# STM32N655 register map
File version: 1.0
CPU: CM55 r0p1, little endian, no MPU, FPU, vendor SysTick, 8 interrupt priority bits
Registers are 32-bit, read-write, reset 0x0 unless marked. A register's access mark holds for its fields unless they carry their own. Offsets are from the block's base; [hi:lo] are bit positions; 'fields as' and 'values as' point back to an identical list.

## XSPI1 — Extended-SPI interface
Base 0x48025000
Same registers: XSPI2 0x4802A000, XSPI3 0x4802D000, XSPI1_S 0x58025000, XSPI2_S 0x5802A000, XSPI3_S 0x5802D000
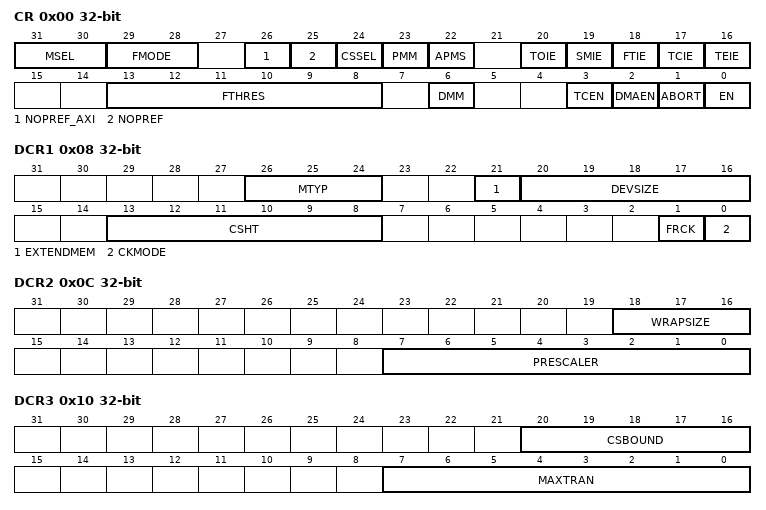
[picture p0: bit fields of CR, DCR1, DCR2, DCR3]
0x00 CR — XSPI control register
  [31:30] MSEL — Flash select
  [29:28] FMODE — Functional mode
  [26] NOPREF_AXI — no prefetch for signaled AXI transactions
  [25] NOPREF — no prefetch data
  [24] CSSEL — chip select selection
  [23] PMM — Polling match mode
  [22] APMS — Automatic status-polling mode stop
  [20] TOIE — Timeout interrupt enable
  [19] SMIE — Status match interrupt enable
  [18] FTIE — FIFO threshold interrupt enable
  [17] TCIE — Transfer complete interrupt enable
  [16] TEIE — Transfer error interrupt enable
  [13:8] FTHRES — FIFO threshold level
  [6] DMM — Dual-memory configuration
  [3] TCEN — Timeout counter enable
  [2] DMAEN — DMA enable
  [1] ABORT — Abort request
  [0] EN — Enable
0x08 DCR1 access per field — XSPI device configuration register 1
  [26:24] MTYP rw — Memory type
  [21] EXTENDMEM rw — extended memory support
  [20:16] DEVSIZE rw — Device size
  [13:8] CSHT rw — Chip-select high time
  [1] FRCK rw — Free running clock
  [0] CKMODE ro — clock mode 0
0x0C DCR2 — XSPI device configuration register 2
  [18:16] WRAPSIZE
  [7:0] PRESCALER — Clock prescaler
0x10 DCR3 — XSPI device configuration register 3
  [20:16] CSBOUND — NCS boundary
  [7:0] MAXTRAN — Maximum transfer
0x14 DCR4 — XSPI device configuration register 4
  [31:0] REFRESH — Refresh rate
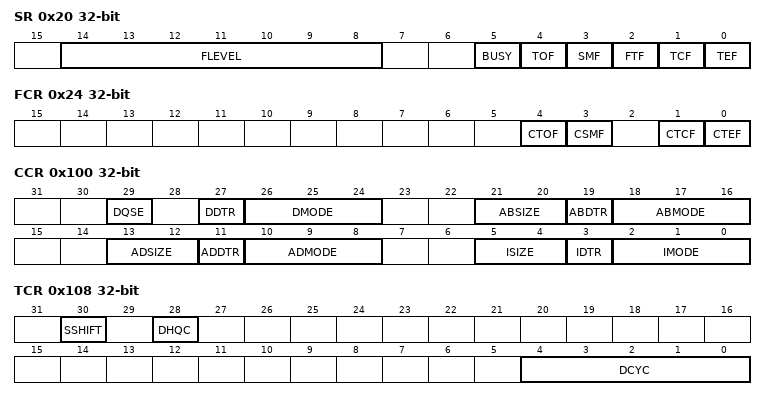
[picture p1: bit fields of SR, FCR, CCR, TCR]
0x20 SR ro — XSPI status register
  [14:8] FLEVEL — FIFO level
  [5] BUSY
  [4] TOF — Timeout flag
  [3] SMF — Status match flag
  [2] FTF — FIFO threshold flag
  [1] TCF — Transfer complete flag
  [0] TEF — Transfer error flag
0x24 FCR wo — XSPI flag clear register
  [4] CTOF — Clear timeout flag
  [3] CSMF — Clear status match flag
  [1] CTCF — Clear transfer complete flag
  [0] CTEF — Clear transfer error flag
0x40 DLR — XSPI data length register
  [31:0] DL
0x48 AR — XSPIaddress register
  [31:0] ADDRESS
0x50 DR — XSPI data register
  [31:0] DATA
0x80 PSMKR — XSPI polling status mask register
  [31:0] MASK — Status mask
0x88 PSMAR — XSPI polling status match register
  [31:0] MATCH
0x90 PIR — XSPI polling interval register
  [15:0] INTERVAL
0x100 CCR — XSPI communication configuration register
  [29] DQSE — DQS enable
  [27] DDTR — Data double transfer rate
  [26:24] DMODE — Data mode
  [21:20] ABSIZE — Alternate bytes size
  [19] ABDTR — Alternate bytes double transfer rate
  [18:16] ABMODE — Alternate-byte mode
  [13:12] ADSIZE — Address size
  [11] ADDTR — Address double transfer rate
  [10:8] ADMODE — Address mode
  [5:4] ISIZE — Instruction size
  [3] IDTR — Instruction double transfer rate
  [2:0] IMODE — Instruction mode
0x108 TCR — XSPI timing configuration register
  [30] SSHIFT — Sample shift
  [28] DHQC — Delay hold quarter cycle
  [4:0] DCYC — Number of dummy cycles
0x110 IR — XSPI instruction register
  [31:0] INSTRUCTION
0x120 ABR — XSPI alternate bytes register
  [31:0] ALTERNATE
0x130 LPTR — XSPI low-power timeout register
  [15:0] TIMEOUT
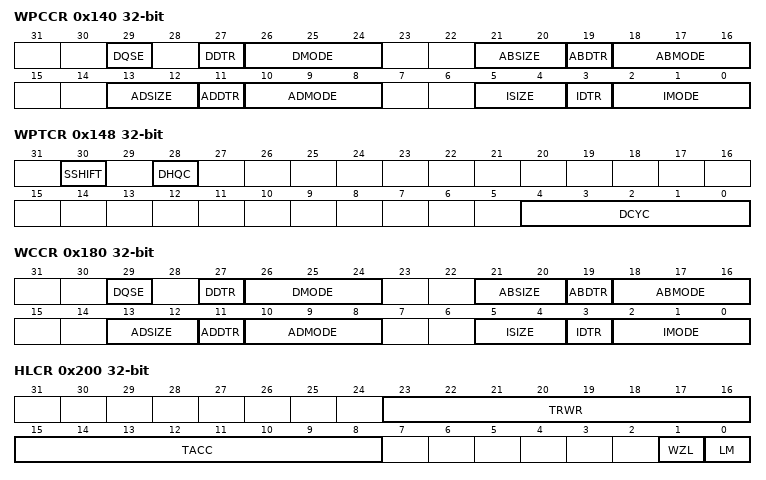
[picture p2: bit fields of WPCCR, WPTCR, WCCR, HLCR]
0x140 WPCCR — XSPI wrap communication configuration register
  fields as CCR
0x148 WPTCR — XSPI wrap timing configuration register
  fields as TCR
0x150 WPIR — XSPI wrap instruction register
  [31:0] INSTRUCTION
0x160 WPABR — XSPI wrap alternate byte register
  [31:0] ALTERNATE
0x180 WCCR — XSPI write communication configuration register
  [29] DQSE — DQS enable
  [27] DDTR — data double transfer rate
  [26:24] DMODE — Data mode
  [21:20] ABSIZE — Alternate bytes size
  [19] ABDTR — Alternate bytes double-transfer rate
  [18:16] ABMODE — Alternate-byte mode
  [13:12] ADSIZE — Address size
  [11] ADDTR — Address double transfer rate
  [10:8] ADMODE — Address mode
  [5:4] ISIZE — Instruction size
  [3] IDTR — Instruction double transfer rate
  [2:0] IMODE — Instruction mode
0x188 WTCR — XSPI write timing configuration register
  [4:0] DCYC — Number of dummy cycles
0x190 WIR — XSPI write instruction register
  [31:0] INSTRUCTION
0x1A0 WABR — XSPI write alternate byte register
  [31:0] ALTERNATE
0x200 HLCR — XSPI HyperBus latency configuration register
  [23:16] TRWR — Read write recovery time
  [15:8] TACC
  [1] WZL — Write zero latency
  [0] LM — Latency mode
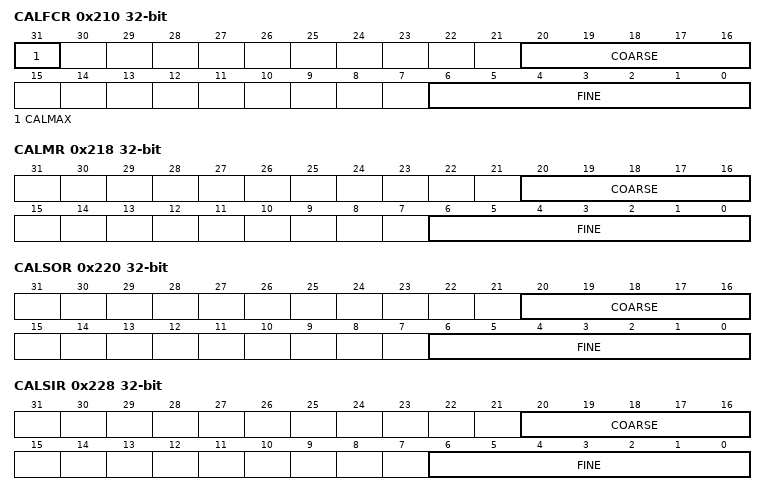
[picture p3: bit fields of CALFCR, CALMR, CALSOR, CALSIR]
0x210 CALFCR ro — XSPI full-cycle calibration configuration
  [31] CALMAX — Max value
  [20:16] COARSE
  [6:0] FINE
0x218 CALMR — XSPI DLL master calibration configuration
  [20:16] COARSE, [6:0] FINE
0x220 CALSOR — XSPI DLL slave output calibration configuration
  [20:16] COARSE, [6:0] FINE
0x228 CALSIR — XSPI DLL slave input calibration configuration
  [20:16] COARSE, [6:0] FINE
